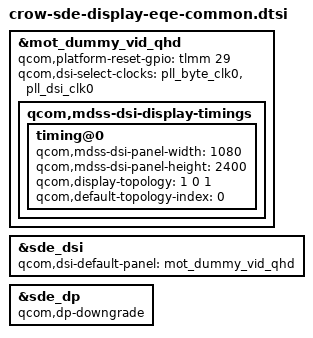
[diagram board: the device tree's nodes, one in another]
/* this is original from crow-sde-display-mtp.dtsi */

#include "crow-sde-display.dtsi"
#include "dsi-panel-mot-dummy-qhd-video.dtsi"


&mot_dummy_vid_qhd {
	qcom,platform-reset-gpio = <&tlmm 29 0>;
	qcom,dsi-select-clocks = "pll_byte_clk0", "pll_dsi_clk0";
	qcom,mdss-dsi-display-timings {
		timing@0 {
			qcom,mdss-dsi-panel-width = <1080>;
			qcom,mdss-dsi-panel-height = <2400>;
			qcom,display-topology = <1 0 1>;
			qcom,default-topology-index = <0>;
        };
    };
};


&sde_dsi {
	qcom,dsi-default-panel = <&mot_dummy_vid_qhd>;
};

&sde_dp {
	qcom,dp-downgrade;
};

